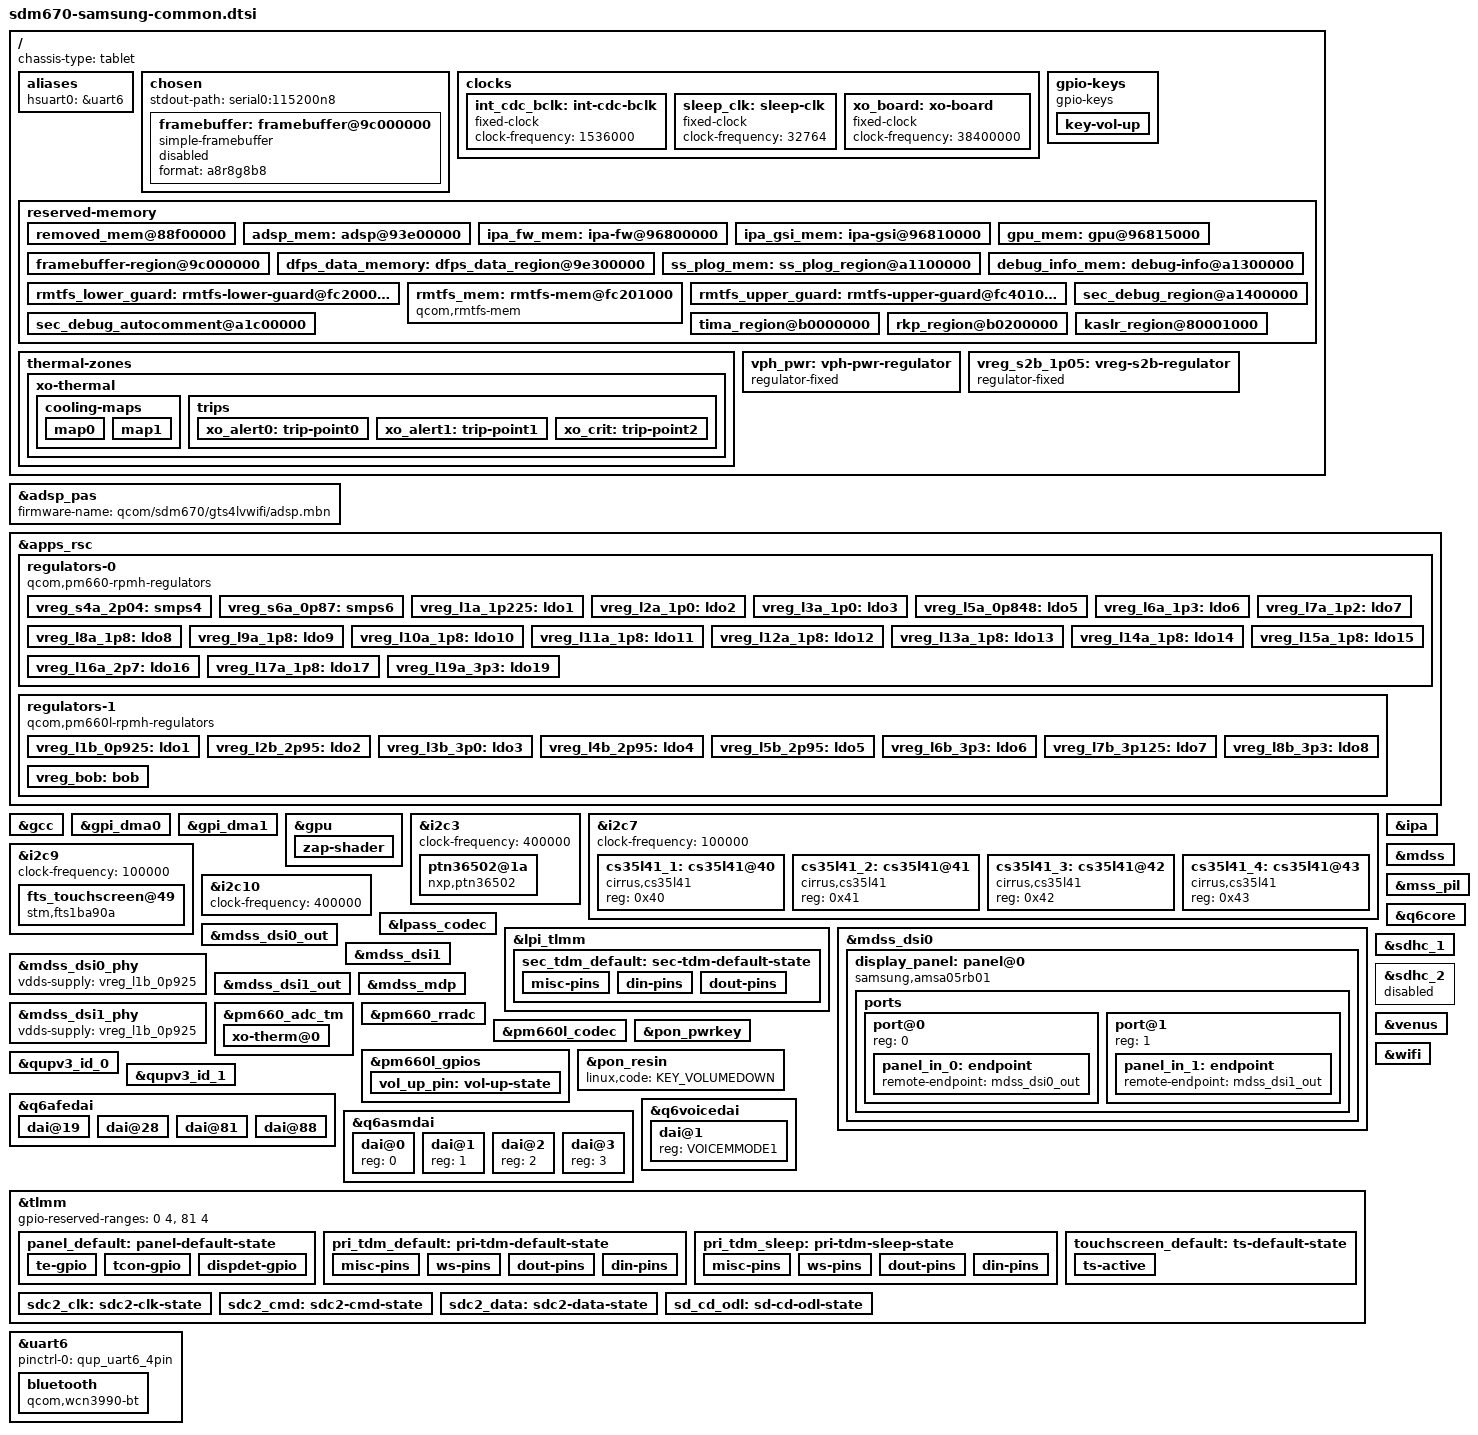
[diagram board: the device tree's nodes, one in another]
// SPDX-License-Identifier: GPL-2.0
/*
 * Device tree for the Samsung Galaxy Tab S5e, adapted from the sdm670-google-common device tree,
 *
 * Copyright (c) 2024, Goldenkrew3000. All rights reserved.
 */

#include <dt-bindings/firmware/qcom,scm.h>
#include <dt-bindings/gpio/gpio.h>
#include <dt-bindings/input/input.h>
#include <dt-bindings/leds/common.h>
#include <dt-bindings/pinctrl/qcom,pmic-gpio.h>
#include <dt-bindings/power/qcom-rpmpd.h>
#include <dt-bindings/sound/qcom,q6afe.h>
#include <dt-bindings/sound/qcom,q6asm.h>
#include <dt-bindings/sound/qcom,q6voice.h>
#include "sdm670.dtsi"
#include "pm660.dtsi"
#include "pm660l.dtsi"

/delete-node/ &rmtfs_mem;
/delete-node/ &spss_mem;
/delete-node/ &adsp_mem;
/delete-node/ &ipa_fw_mem;
/delete-node/ &ipa_gsi_mem;
/delete-node/ &gpu_mem;

/ {
    chassis-type = "tablet";

    aliases {
        hsuart0 = &uart6; // Bluetooth
    };

    chosen {
        stdout-path = "serial0:115200n8";

        #address-cells = <2>;
        #size-cells = <2>;
        ranges;
        framebuffer: framebuffer@9c000000 {
            compatible = "simple-framebuffer";
            format = "a8r8g8b8";
            status = "disabled";
        };
    };

    clocks {
        int_cdc_bclk: int-cdc-bclk {
            compatible = "fixed-clock";
            #clock-cells = <0>;
            clock-frequency = <1536000>;
        };

        sleep_clk: sleep-clk {
            compatible = "fixed-clock";
            #clock-cells = <0>;
            clock-frequency = <32764>;
        };

        xo_board: xo-board {
            compatible = "fixed-clock";
            #clock-cells = <0>;
            clock-frequency = <38400000>;
        };
    };

    gpio-keys {
        compatible = "gpio-keys";
        autorepeat;

        pinctrl-names = "default";
        pinctrl-0 = <&vol_up_pin>;

        key-vol-up {
            label = "Volume Up";
            linux,code = <KEY_VOLUMEUP>;
            gpios = <&pm660l_gpios 7 GPIO_ACTIVE_LOW>;
        };
    };

    reserved-memory {
        // Note: Some memory (0x85fc0000 - 0x2f40000) is marked as removed_region in downstream
        // Another note: Samsung has modified the dtb EXTENSIVELY in the DTBO.... WHYYYY
        
        // So basically, all combined, plus making room for SMEM etc, 0x88F00000 with length of 0x400000 should be reserved
        removed_mem@88f00000 {
            // The device crashes without this area of memory reserved
            reg = <0 0x88f00000 0 0x400000>;
            no-map;
        };

        // Parts that have been modified from a DTBO (DTBO ID 1)
        adsp_mem: adsp@93e00000 {
            reg = <0 0x93e00000 0 0x2a00000>;
            no-map;
        };

        // These 3 are defined as 0x96800000 but in dmesg, show 96600000... Not defined in any dtb or dtbo
        // Not to mention this isn't even really possible due to it overlapping with ADSP then. Rolling with the proper way
        ipa_fw_mem: ipa-fw@96800000 {
            reg = <0 0x96800000 0 0x10000>;
            no-map;
        };

        ipa_gsi_mem: ipa-gsi@96810000 {
            reg = <0 0x96810000 0 0x5000>;
            no-map;
        };

        gpu_mem: gpu@96815000 {
            reg = <0 0x96815000 0 0x2000>;
            no-map;
        };

        framebuffer-region@9c000000 {
            reg = <0 0x9c000000 0 0x2300000>;
            no-map;
        };

        dfps_data_memory: dfps_data_region@9e300000 {
            reg = <0x0 0x9e300000 0x0 0x100000>;
            no-map;
        };

        ss_plog_mem: ss_plog_region@a1100000 {
            reg = <0x0 0xa1100000 0x0 0x200000>;
            no-map;
        };

        debug_info_mem: debug-info@a1300000 {
            reg = <0 0xa1300000 0 0x100000>;
            no-map;
        };

        rmtfs_lower_guard: rmtfs-lower-guard@fc200000 {
            reg = <0 0xfc200000 0 0x1000>;
            no-map;
        };

        rmtfs_mem: rmtfs-mem@fc201000 {
            compatible = "qcom,rmtfs-mem";
            reg = <0 0xfc201000 0 0x200000>;
            no-map;

            qcom,client-id = <1>;
            qcom,vmid = <QCOM_SCM_VMID_MSS_MSA>;
        };

        rmtfs_upper_guard: rmtfs-upper-guard@fc401000 {
            reg = <0 0xfc401000 0 0x1000>;
            no-map;
        };

        // From DTBO ID 1 (SAMSUNG WHYYYY)
        sec_debug_region@a1400000 {
            reg = <0 0xa1400000 0 0x800000>;
            no-map;
        };

        sec_debug_autocomment@a1c00000 {
            reg = <0 0xa1c00000 0 0x1000>;
            no-map;
        };

        tima_region@b0000000 {
            reg = <0 0xb0000000 0 0x200000>;
            no-map;
        };

        rkp_region@b0200000 {
            // Not technically a no-map, but defined so in dmesg
            reg = <0 0xb0200000 0 0x1500000>;
            no-map;
        };

        kaslr_region@80001000 {
            // Also not technically a no-map
            reg = <0 0x80001000 0 0x1000>;
            no-map;
        };
    };

    // TODO: Implement sound here
    
    // TODO: Verify thermal situation
    thermal-zones {
        xo-thermal {
            polling-delay-passive = <250>;
            polling-delay = <1000>;

            thermal-sensors = <&pm660_adc_tm 0>;

            cooling-maps {
                map0 {
                    trip = <&xo_alert0>;
                    cooling-device = <&CPU6 THERMAL_NO_LIMIT THERMAL_NO_LIMIT>,
                             <&CPU7 THERMAL_NO_LIMIT THERMAL_NO_LIMIT>;

                };

                map1 {
                    trip = <&xo_alert1>;
                    cooling-device = <&CPU0 THERMAL_NO_LIMIT THERMAL_NO_LIMIT>,
                             <&CPU1 THERMAL_NO_LIMIT THERMAL_NO_LIMIT>,
                             <&CPU2 THERMAL_NO_LIMIT THERMAL_NO_LIMIT>,
                             <&CPU3 THERMAL_NO_LIMIT THERMAL_NO_LIMIT>,
                             <&CPU4 THERMAL_NO_LIMIT THERMAL_NO_LIMIT>,
                             <&CPU5 THERMAL_NO_LIMIT THERMAL_NO_LIMIT>;

                };
            };

            trips {
                xo_alert0: trip-point0 {
                    temperature = <47000>;
                    hysteresis = <1000>;
                    type = "passive";
                };

                xo_alert1: trip-point1 {
                    temperature = <52000>;
                    hysteresis = <1000>;
                    type = "passive";
                };

                xo_crit: trip-point2 {
                    temperature = <59000>;
                    hysteresis = <1000>;
                    type = "critical";
                };
            };
        };
    };

    // P.S. Not sure if this is needed or not
    vph_pwr: vph-pwr-regulator {
        compatible = "regulator-fixed";
        regulator-name = "vph_pwr";
        regulator-min-microvolt = <3312000>;
        regulator-max-microvolt = <3312000>;

        regulator-always-on;
        regulator-boot-on;
    };

    // Also not sure if this is needed
    vreg_s2b_1p05: vreg-s2b-regulator {
        compatible = "regulator-fixed";
        regulator-name = "vreg_s2b";
        regulator-min-microvolt = <1050000>;
        regulator-max-microvolt = <1050000>;
    };
};

&adsp_pas {
    firmware-name = "qcom/sdm670/gts4lvwifi/adsp.mbn";
    status = "okay";
};

&apps_rsc {
    regulators-0 {
        compatible = "qcom,pm660-rpmh-regulators";
        qcom,pmic-id = "a";

        vdd-s1-supply = <&vph_pwr>;
        vdd-s2-supply = <&vph_pwr>;
        vdd-s3-supply = <&vph_pwr>;
        vdd-s4-supply = <&vph_pwr>;
        vdd-s5-supply = <&vph_pwr>;
        vdd-s6-supply = <&vph_pwr>;

        vdd-l1-l6-l7-supply = <&vreg_s6a_0p87>;
        vdd-l2-l3-supply = <&vreg_s2b_1p05>;
        vdd-l5-supply = <&vreg_s2b_1p05>;
        vdd-l8-l9-l10-l11-l12-l13-l14-supply = <&vreg_s4a_2p04>;
        vdd-l15-l16-l17-l18-l19-supply = <&vreg_bob>;

        vreg_s4a_2p04: smps4 {
            regulator-min-microvolt = <1808000>;
            regulator-max-microvolt = <2040000>;
            regulator-enable-ramp-delay = <200>;
        };

        vreg_s6a_0p87: smps6 {
            regulator-min-microvolt = <1224000>;
            regulator-max-microvolt = <1352000>;
            regulator-enable-ramp-delay = <150>;
        };

        /* LDOs */
        vreg_l1a_1p225: ldo1 {
            regulator-min-microvolt = <1200000>;
            regulator-max-microvolt = <1250000>;
            regulator-enable-ramp-delay = <250>;
        };

        vreg_l2a_1p0: ldo2 {
            regulator-min-microvolt = <1000000>;
            regulator-max-microvolt = <1000000>;
            regulator-enable-ramp-delay = <250>;
        };

        vreg_l3a_1p0: ldo3 {
            regulator-min-microvolt = <1000000>;
            regulator-max-microvolt = <1000000>;
            regulator-enable-ramp-delay = <250>;
        };

        vreg_l5a_0p848: ldo5 {
            regulator-min-microvolt = <800000>;
            regulator-max-microvolt = <800000>;
            regulator-enable-ramp-delay = <250>;
        };

        vreg_l6a_1p3: ldo6 {
            regulator-min-microvolt = <1248000>;
            regulator-max-microvolt = <1304000>;
            regulator-enable-ramp-delay = <250>;
        };

        vreg_l7a_1p2: ldo7 {
            regulator-min-microvolt = <1200000>;
            regulator-max-microvolt = <1200000>;
            regulator-enable-ramp-delay = <250>;
        };

        vreg_l8a_1p8: ldo8 {
            regulator-min-microvolt = <1800000>;
            regulator-max-microvolt = <1800000>;
            regulator-enable-ramp-delay = <250>;
            regulator-always-on;
        };

        vreg_l9a_1p8: ldo9 {
            regulator-min-microvolt = <1800000>;
            regulator-max-microvolt = <1800000>;
            regulator-enable-ramp-delay = <250>;
        };

        vreg_l10a_1p8: ldo10 {
            regulator-min-microvolt = <1800000>;
            regulator-max-microvolt = <1800000>;
            regulator-enable-ramp-delay = <250>;
        };

        vreg_l11a_1p8: ldo11 {
            regulator-min-microvolt = <1800000>;
            regulator-max-microvolt = <1800000>;
            regulator-enable-ramp-delay = <250>;
        };

        vreg_l12a_1p8: ldo12 {
            regulator-min-microvolt = <1800000>;
            regulator-max-microvolt = <1800000>;
            regulator-enable-ramp-delay = <250>;
        };

        vreg_l13a_1p8: ldo13 {
            regulator-min-microvolt = <1800000>;
            regulator-max-microvolt = <1800000>;
            regulator-enable-ramp-delay = <250>;
        };

        vreg_l14a_1p8: ldo14 {
            regulator-min-microvolt = <1800000>;
            regulator-max-microvolt = <1800000>;
            regulator-enable-ramp-delay = <250>;
        };

        vreg_l15a_1p8: ldo15 {
            regulator-min-microvolt = <1800000>;
            regulator-max-microvolt = <2950000>;
            regulator-enable-ramp-delay = <250>;
        };

        vreg_l16a_2p7: ldo16 {
            regulator-min-microvolt = <2696000>;
            regulator-max-microvolt = <2696000>;
            regulator-enable-ramp-delay = <250>;
        };

        vreg_l17a_1p8: ldo17 {
            regulator-min-microvolt = <1800000>;
            regulator-max-microvolt = <2950000>;
            regulator-enable-ramp-delay = <250>;
        };

        vreg_l19a_3p3: ldo19 {
            regulator-min-microvolt = <3000000>;
            regulator-max-microvolt = <3312000>;
            regulator-enable-ramp-delay = <250>;
        };
    };

    regulators-1 {
        compatible = "qcom,pm660l-rpmh-regulators";
        qcom,pmic-id = "b";

        vdd-s1-supply = <&vph_pwr>;
        vdd-s2-supply = <&vph_pwr>;
        vdd-s3-s4-supply = <&vph_pwr>;
        vdd-s5-supply = <&vph_pwr>;

        vdd-l1-l9-l10-supply = <&vreg_s2b_1p05>;
        vdd-l2-supply = <&vreg_bob>;
        vdd-l3-l5-l7-l8-supply = <&vreg_bob>;
        vdd-l4-l6-supply = <&vreg_bob>;
        vdd-bob-supply = <&vph_pwr>;

        /* LDOs */
        vreg_l1b_0p925: ldo1 {
            regulator-min-microvolt = <880000>;
            regulator-max-microvolt = <900000>;
            regulator-enable-ramp-delay = <250>;
        };

        vreg_l2b_2p95: ldo2 {
            regulator-min-microvolt = <1800000>;
            regulator-max-microvolt = <2960000>;
            regulator-enable-ramp-delay = <250>;
        };

        vreg_l3b_3p0: ldo3 {
            regulator-min-microvolt = <2800000>;
            regulator-max-microvolt = <3008000>;
            regulator-enable-ramp-delay = <250>;
        };

        vreg_l4b_2p95: ldo4 {
            regulator-min-microvolt = <2960000>;
            regulator-max-microvolt = <2960000>;
            regulator-enable-ramp-delay = <250>;
        };

        vreg_l5b_2p95: ldo5 {
            regulator-min-microvolt = <2960000>;
            regulator-max-microvolt = <2960000>;
            regulator-enable-ramp-delay = <250>;
        };

        vreg_l6b_3p3: ldo6 {
            regulator-min-microvolt = <3000000>;
            regulator-max-microvolt = <3300000>;
            regulator-enable-ramp-delay = <250>;
        };

        vreg_l7b_3p125: ldo7 {
            regulator-min-microvolt = <3088000>;
            regulator-max-microvolt = <3100000>;
            regulator-enable-ramp-delay = <250>;
        };

        vreg_l8b_3p3: ldo8 {
            regulator-min-microvolt = <3300000>;
            regulator-max-microvolt = <3312000>;
            regulator-enable-ramp-delay = <250>;
        };

        // Not sure if this is needed
        vreg_bob: bob {
            regulator-min-microvolt = <3296000>;
            regulator-max-microvolt = <3328000>;
            regulator-enable-ramp-delay = <500>;
        };
    };
};

&gcc {
    protected-clocks = <GCC_QSPI_CORE_CLK>,
        <GCC_QSPI_CORE_CLK_SRC>,
        <GCC_QSPI_CNOC_PERIPH_AHB_CLK>;
};

&gpi_dma0 {
    status = "okay";
};

&gpi_dma1 {
    status = "okay";
};

&gpu {
    status = "okay";

    zap-shader {
        memory-region = <&gpu_mem>;
        firmware-name = "qcom/sdm670/gts4lvwifi/a615_zap.mbn";
    };
};

// I2Cs
&i2c3 {
    clock-frequency = <400000>;
    status = "okay";

    ptn36502@1a { // TODO: Actually format this ready for mainline
        // NXP PTN38502 - USB-C Type 3.1 MUX
        compatible = "nxp,ptn36502";
        reg = <0x1a>;
        ptn_en = <&tlmm 15 GPIO_ACTIVE_HIGH>;
        redriver_en = <&tlmm 16 GPIO_ACTIVE_HIGH>;
        con_sel = <&tlmm 25 GPIO_ACTIVE_HIGH>;
    };
};

&i2c7 {
    clock-frequency = <100000>;
    status = "okay";

    // 4x CS35L41 Audio AMPs
    cs35l41_1: cs35l41@40 {
        #sound-dai-cells = <1>;
        compatible = "cirrus,cs35l41";
        reg = <0x40>;
    };

    cs35l41_2: cs35l41@41 {
        #sound-dai-cells = <1>;
        compatible = "cirrus,cs35l41";
        reg = <0x41>;
    };

    cs35l41_3: cs35l41@42 {
        #sound-dai-cells = <1>;
        compatible = "cirrus,cs35l41";
        reg = <0x42>;
    };

    cs35l41_4: cs35l41@43 {
        #sound-dai-cells = <1>;
        compatible = "cirrus,cs35l41";
        reg = <0x43>;
    };
};

&i2c9 {
    clock-frequency = <100000>;
    status = "okay";

    fts_touchscreen@49 {
        compatible = "stm,fts1ba90a";
        reg = <0x49>;

        pinctrl-names = "default";
        pinctrl-0 = <&touchscreen_default>;

        touchscreen-size-x = <1600>;
        touchscreen-size-y = <2560>;

        interrupt-parent = <&tlmm>;
        interrupts = <123 0x2008>;
        vdd-supply = <&vreg_l11a_1p8>;
        avdd-supply = <&vreg_l6b_3p3>;
        
        status = "okay";
    };
};

&i2c10 {
    clock-frequency = <400000>;
    status = "okay";

    // TODO - Untested audio stuff
};

&ipa {
    firmware-name = "qcom/sdm670/gts4lvwifi/ipa_fws.mbn";
    status = "okay";
};

// TODO Check the next two things
&lpass_codec {
    clocks = <&q6afecc LPASS_CLK_ID_INT_MCLK_0 LPASS_CLK_ATTRIBUTE_COUPLE_NO>,
         <&int_cdc_bclk>;
    clock-names = "mclk", "ahbix-clk";

    assigned-clocks = <&q6afecc LPASS_CLK_ID_INT_MCLK_0 LPASS_CLK_ATTRIBUTE_COUPLE_NO>;
    assigned-clock-rates = <9600000>;

    status = "okay";
};

&lpi_tlmm {
    sec_tdm_default: sec-tdm-default-state {
        misc-pins {
            pins = "gpio8", "gpio9";
            function = "sec_tdm";
            drive-strength = <8>;
            bias-disable;
        };

        din-pins {
            pins = "gpio10";
            function = "sec_tdm_din";
            drive-strength = <8>;
            bias-disable;
        };

        dout-pins {
            pins = "gpio11";
            function = "sec_tdm_dout";
            drive-strength = <8>;
            bias-disable;
        };
    };
};

&mdss {
    status = "okay";
};

// Based off of the Xiaomi Elish (Similar SoC and also a Dual DSI panel)
&mdss_dsi0 {
    // VDDA HERE
    qcom,dual-dsi-mode;
    qcom,sync-dual-dsi;
    qcom,master-dsi;
    status = "okay";

    display_panel: panel@0 {
        reg = <0>;
        compatible = "samsung,amsa05rb01";

        // VDDIO HERE
       reset-gpios = <&tlmm 126 GPIO_ACTIVE_HIGH>;
       pinctrl-names = "default";
       pinctrl-0 = <&panel_default>;

       // 10 is TE, held to HIGH here

       // 10 -> TE (I think is pulled low for panel in use)
       // 21 -> LCDVDD (OCTA)
       // 126 -> RST
       // 79 -> TCON (Pulled up for panel in use)
       // 26 -> 'Disp Det' I think just off

        status = "okay";

        ports {
            #address-cells = <1>;
            #size-cells = <0>;

            port@0 {
                reg = <0>;

                panel_in_0: endpoint {
                    remote-endpoint = <&mdss_dsi0_out>;
                };
            };

            port@1 {
                reg = <1>;

                panel_in_1: endpoint {
                    remote-endpoint = <&mdss_dsi1_out>;
                };
            };
        };
    };
};

&mdss_dsi0_out {
    data-lanes = <0 1 2 3>;
    remote-endpoint = <&panel_in_0>;
};

&mdss_dsi0_phy {
    vdds-supply = <&vreg_l1b_0p925>;
    // PHY type was here in xiaomi device tree
    status = "okay";
};

&mdss_dsi1 {
    // Needs VDDA here
    qcom,dual-dsi-mode;
    qcom,sync-dual-dsi;
    assigned-clock-parents = <&mdss_dsi0_phy 0>, <&mdss_dsi0_phy 1>;
    status = "okay";
};

&mdss_dsi1_out {
    data-lanes = <0 1 2 3>;
    remote-endpoints = <&panel_in_1>;
};

&mdss_dsi1_phy {
    vdds-supply = <&vreg_l1b_0p925>;
    // PHY type was here in xiaomi device tree
    status = "okay";
};

&mdss_mdp {
    status = "okay";
};

&mss_pil {
    firmware-name = "qcom/sdm670/gts4lvwifi/mba.mbn", "qcom/sdm670/gts4lvwifi/modem.mbn";
    status = "okay";
};

// TODO Check this
&pm660_adc_tm {
    status = "okay";

    xo-therm@0 {
        reg = <0>;
        io-channels = <&pm660_adc ADC5_XO_THERM_100K_PU>;
        qcom,hw-settle-time-us = <200>;
        qcom,pre-scaling = <1 20>;
        qcom,ratiometric;
    };
};

// PM660 Charger stuff here (And fuelgauge)

&pm660_rradc {
    status = "okay";
};

// I think audio stuff
&pm660l_codec {
    clocks = <&q6afecc LPASS_CLK_ID_INT_MCLK_0 LPASS_CLK_ATTRIBUTE_COUPLE_NO>;
    clock-names = "mclk";

    assigned-clocks = <&q6afecc LPASS_CLK_ID_INT_MCLK_0 LPASS_CLK_ATTRIBUTE_COUPLE_NO>;
    assigned-clock-rates = <9600000>;

    vdd-cdc-io-supply = <&vreg_l10a_1p8>;
    vdd-cdc-tx-rx-cx-supply = <&vreg_l1b_0p925>;
    vdd-micbias-supply = <&vreg_l7b_3p125>;

    qcom,micbias-lvl = <2500>;
    qcom,micbias1-ext-cap;

    status = "okay";
};

&pm660l_gpios {
    vol_up_pin: vol-up-state {
        pins = "gpio7";
        function = "normal";
        qcom,drive-strength = <PMIC_GPIO_STRENGTH_NO>;
        input-enable;
        bias-pull-up;
    };
};

&pon_pwrkey {
    status = "okay";
};

&pon_resin {
    linux,code = <KEY_VOLUMEDOWN>;
    status = "okay";
};

&qupv3_id_0 {
    status = "okay";
};

&qupv3_id_1 {
    status = "okay";
};

// Not sure whether this Q6 stuff is needed
&q6afedai {
    dai@19 {
        reg = <PRIMARY_TDM_TX_0>;

        qcom,tdm-sync-mode = <0>;
        qcom,tdm-sync-src = <1>;
        qcom,tdm-data-out = <0>;
        qcom,tdm-invert-sync = <0>;
        qcom,tdm-data-delay = <1>;
        qcom,tdm-data-align = <0>;
    };

    dai@28 {
        reg = <SECONDARY_TDM_RX_0>;

        qcom,tdm-sync-mode = <0>;
        qcom,tdm-sync-src = <1>;
        qcom,tdm-data-out = <0>;
        qcom,tdm-invert-sync = <0>;
        qcom,tdm-data-delay = <1>;
        qcom,tdm-data-align = <0>;
    };

    dai@81 {
        reg = <INT0_MI2S_RX>;
        qcom,sd-lines = <0 1>;
    };

    dai@88 {
        reg = <INT3_MI2S_TX>;
        qcom,sd-lines = <0 1>;
    };
};

&q6asmdai {
    dai@0 {
        reg = <0>;
    };

    dai@1 {
        reg = <1>;
    };

    dai@2 {
        reg = <2>;
    };

    dai@3 {
        reg = <3>;
    };
};

&q6core {
    qcom,acdb-name = "qcom/sdm670/sargo/Global_cal.acdb";
};

&q6voicedai {
    dai@1 {
        reg = <VOICEMMODE1>;
    };
};

&sdhc_1 {
    // Internal eMMC
    supports-cqe;
    mmc-hs200-1_8v;
    mmc-hs400-1_8v;
    mmc-ddr-1_8v;

    qcom,ddr-config = <0xc3040873>;

    vmmc-supply = <&vreg_l4b_2p95>;
    vqmmc-supply = <&vreg_l8a_1p8>;

    status = "okay";
};

&sdhc_2 {
    // External MMC, causes kernel panic if enabled currently
    pinctrl-names = "default";
    pinctrl-0 = <&sdc2_clk &sdc2_cmd &sdc2_data &sd_cd_odl>;

    vmmc-supply = <&vreg_l5b_2p95>;
    vqmmc-supply = <&vreg_l2b_2p95>;

    cd-gpios = <&tlmm 96 GPIO_ACTIVE_LOW>;

    status = "disabled";
};

// SPI stuff here for audio codec

&tlmm {
    gpio-reserved-ranges = <0 4>, <81 4>;

    // TODO: Add audio stuff

    // TODO: Make panel functional
    panel_default: panel-default-state {
        te-gpio {
            pins = "gpio10";
            function = "mdp_vsync";
            drive-strength = <2>;
            bias-pull-down;
        };

        tcon-gpio {
            pins = "gpio79";
            function = "gpio";
            drive-strength = <8>;
            bias-pull-down;
        };

        dispdet-gpio {
            pins = "gpio26";
            function = "gpio";
            drive-strength = <2>;
            bias-disable;
            // Technically an input but i dont care
        };

        /*
        mode-pins {
            pins = "gpio76";
            function = "gpio";
            drive-strength = <8>;
            bias-disable;
        };*/
    };

    pri_tdm_default: pri-tdm-default-state {
        misc-pins {
            pins = "gpio65";
            function = "pri_mi2s";
            drive-strength = <8>;
        };

        ws-pins {
            pins = "gpio66";
            function = "pri_mi2s_ws";
            drive-strength = <8>;
        };

        dout-pins {
            pins = "gpio67";
            function = "pri_mi2s";
            drive-strength = <8>;
        };

        din-pins {
            pins = "gpio68";
            function = "pri_mi2s";
            drive-strength = <8>;
        };
    };

    pri_tdm_sleep: pri-tdm-sleep-state {
        misc-pins {
            pins = "gpio65";
            function = "pri_mi2s";
            drive-strength = <2>;
            bias-pull-down;
        };

        ws-pins {
            pins = "gpio66";
            function = "pri_mi2s_ws";
            drive-strength = <2>;
            bias-pull-down;
        };

        dout-pins {
            pins = "gpio67";
            function = "pri_mi2s";
            drive-strength = <2>;
            bias-pull-down;
        };

        din-pins {
            pins = "gpio68";
            function = "pri_mi2s";
            drive-strength = <2>;
            bias-pull-down;
        };
    };

    // More audio coded stuff here

    touchscreen_default: ts-default-state {
        ts-active {
            pins = "gpio123";
            function = "gpio";
            input-enable;
            bias-disable;
        };
    };

    // SDHC2 pin control
    sdc2_clk: sdc2-clk-state {
        pins = "sdc2_clk";
        bias-disable;
        drive-strength = <16>;
    };

    sdc2_cmd: sdc2-cmd-state {
        pins = "sdc2_cmd";
        bias-pull-up;
        drive-strength = <10>;
    };

    sdc2_data: sdc2-data-state {
        pins = "sdc2_data";
        bias-pull-up;
        drive-strength = <10>;
    };

    sd_cd_odl: sd-cd-odl-state {
        pins = "gpio96";
        drive-strength = <2>;
        bias-disable;
    };
};

&uart6 {
    // Bluetooth
    pinctrl-0 = <&qup_uart6_4pin>;
    status = "okay";

    bluetooth {
        compatible = "qcom,wcn3990-bt";
        vddio-supply = <&vph_pwr>;
        vddxo-supply = <&vreg_l9a_1p8>;
        vddrf-supply = <&vreg_l6a_1p3>;
        vddch0-supply = <&vreg_l19a_3p3>;
        max-speed = <3200000>;
    };
};

// USB stuff here, currently non functional due to USB2 being muxed through the PMIC
// TODO: Actually implement USB3 support
/*
&usb_1 {
    qcom,select-utmi-as-pipe-clk;
    //status = "okay";
};

&usb_1_hsphy {
    //status = "okay";
};

&usb_1_qmpphy {
    //status = "okay";
};
*/

&venus {
    firmware-name = "qcom/sdm670/gts4lvwifi/venus.mbn";
    status = "okay";
};

&wifi {
    vdd-0.8-cx-mx-supply = <&vreg_l5a_0p848>;
    vdd-1.8-xo-supply = <&vreg_l9a_1p8>;
    vdd-1.3-rfa-supply = <&vreg_l6a_1p3>;
    vdd-3.3-ch0-supply = <&vreg_l19a_3p3>;

    qcom,snoc-host-cap-8bit-quirk;

    status = "okay";
};
